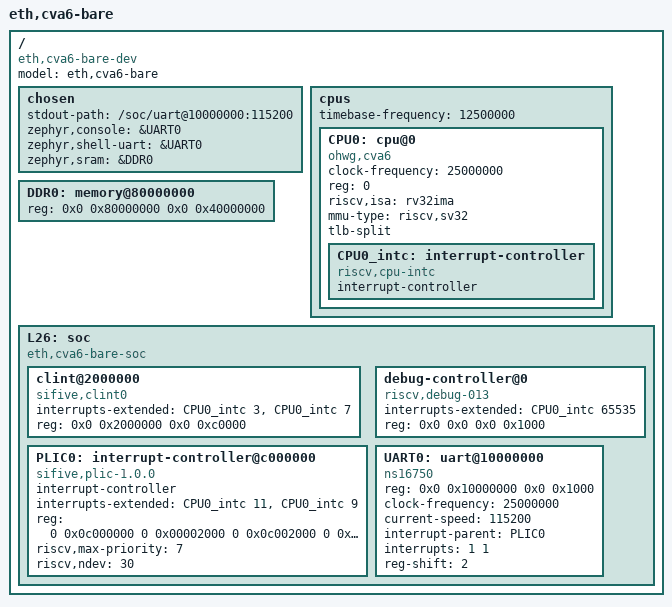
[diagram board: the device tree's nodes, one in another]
/dts-v1/;

#include <skeleton.dtsi>

/ {
  #address-cells = <2>;
  #size-cells = <2>;
  compatible = "eth,cva6-bare-dev";
  model = "eth,cva6-bare";
  chosen {
    stdout-path = "/soc/uart@10000000:115200";
    zephyr,console = &UART0;
    zephyr,shell-uart = &UART0;
    zephyr,sram = &DDR0;
    //zephyr,flash = &DDR0;
    //tick-timer =  "/cpus/cpu@0";
  };
  cpus {
    #address-cells = <1>;
    #size-cells = <0>;
    timebase-frequency = <12500000>; // 22,5 MHz
    CPU0: cpu@0 {
      clock-frequency = <25000000>; // 45 MHz
      device_type = "cpu";
      reg = <0>;
      status = "okay";
      compatible = "ohwg,cva6", "riscv";
      riscv,isa = "rv32ima";
      mmu-type = "riscv,sv32";
      tlb-split;
      // HLIC - hart local interrupt controller
      CPU0_intc: interrupt-controller {
        #interrupt-cells = <1>;
        interrupt-controller;
        compatible = "riscv,cpu-intc";
      };
    };
  };
  DDR0: memory@80000000 {
    device_type = "memory";
    reg = <0x0 0x80000000 0x0 0x40000000>;
  };
  L26: soc {
    #address-cells = <2>;
    #size-cells = <2>;
    compatible = "eth,cva6-bare-soc", "simple-bus";
    ranges;
    clint@2000000 {
      compatible = "sifive,clint0";
      interrupts-extended = <&CPU0_intc 3 &CPU0_intc 7>;
      reg = <0x0 0x2000000 0x0 0xc0000>;
      reg-names = "control";
    };
    PLIC0: interrupt-controller@c000000 {
      #address-cells = <0>;
      #interrupt-cells = <2>;
      compatible = "sifive,plic-1.0.0";
      interrupt-controller;
      interrupts-extended = <&CPU0_intc 11 &CPU0_intc 9>;
      // reg = <0x0 0xc000000 0x0 0x4000000>;
      // reg and reg-names copied from other dts, required for plic generation, to be verified
      reg = <0 0x0c000000 0 0x00002000
          0 0x0c002000 0 0x001fe000
          0 0x0c200000 0 0x03e00000>;
      reg-names = "prio", "irq_en", "reg";
      riscv,max-priority = <7>;
      riscv,ndev = <30>;
    };
    debug-controller@0 {
      compatible = "riscv,debug-013";
      interrupts-extended = <&CPU0_intc 65535>;
      reg = <0x0 0x0 0x0 0x1000>;
      reg-names = "control";
    };
    UART0: uart@10000000 {
      compatible = "ns16750", "ns16550";
      reg = <0x0 0x10000000 0x0 0x1000>;
      clock-frequency = <25000000>;
      current-speed = <115200>;
      interrupt-parent = <&PLIC0>;
      interrupts = <1 1>;
      reg-shift = <2>; // regs are spaced on 32 bit boundary
    };
  };
};
